# PRM_MPU register map
Vendor: Texas Instruments
Peripheral module from a debugger description file (folder am437x).
Registers are 32-bit, access per field, no defined reset value unless marked. A register's access mark holds for its fields unless they carry their own. Offsets are as the file gives them; lines under a group give offsets from that group; [hi:lo] are bit positions; {n}, {i} and the like mark numbered series; 'fields as' and 'values as' point back to an identical list; <NAME> marks a mode.

## PRM_MPU
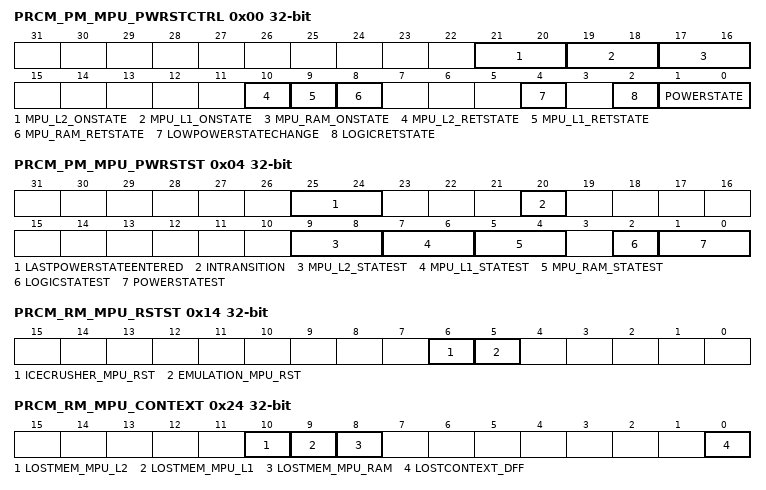
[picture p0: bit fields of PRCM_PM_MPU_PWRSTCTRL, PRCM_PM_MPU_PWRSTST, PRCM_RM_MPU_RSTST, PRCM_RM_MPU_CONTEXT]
0x00 PRCM_PM_MPU_PWRSTCTRL — This register controls the MPU power state to reach upon mpu domain sleep transition
  [21:20] MPU_L2_ONSTATE ro — Default power domain memory state when domain is ON.
    3=en_1_0x3 (Memory bank is on when the domain is ON.)
  [19:18] MPU_L1_ONSTATE ro — Default power domain memory state when domain is ON.
    3=en_1_0x3 (Memory bank is on when the domain is ON.)
  [17:16] MPU_RAM_ONSTATE ro — Default power domain memory state when domain is ON.
    3=en_1_0x3 (Memory bank is on when the domain is ON.)
  [10] MPU_L2_RETSTATE rw — L2 bank state when domain is retention.
    1=en_2_0x1 (Memory is retained when domain is in RETENTION state.); 0=en_1_0x0 (Memory is off when the domain is in the RETENTION state.)
  [9] MPU_L1_RETSTATE rw — L1 bank state when domain is retention.
    values as MPU_L2_RETSTATE
  [8] MPU_RAM_RETSTATE rw — MPU RAM bank state when domain is retention.
    values as MPU_L2_RETSTATE
  [4] LOWPOWERSTATECHANGE rw — Power state change request when domain has already performed a sleep transition. [[br]]Allows going into deeper low power state without waking up the power domain.
    1=en_2_0x1 (Request a low power state change. This bit is automatically cleared when the power state is effectively changed or when power state is ON.); 0=en_1_0x0 (Do not request a low power state change.)
  [2] LOGICRETSTATE rw — Logic state when power domain is RETENTION
    1=en_2_0x1 (Whole logic is retained when domain is in RETENTION state.); 0=en_1_0x0 (Only retention registers are retained and remaing logic is off when the domain is in RETENTION state.)
  [1:0] POWERSTATE rw — Power state control
    3=en_4_0x3 (ON State); 2=en_3_0x2 (RESERVED); 1=en_2_0x1 (RETENTION state); 0=en_1_0x0 (OFF State)
0x04 PRCM_PM_MPU_PWRSTST — This register provides a status on the current MPU power domain state0. [warm reset insensitive]
  [25:24] LASTPOWERSTATEENTERED rw — Last low power state entered. [[br]]Set to 0x3 upon write of the same only. [[br]]This register is intended for debug purpose only.
    3=en_4_0x3 (Power domain was previously ON-ACTIVE); 2=en_3_0x2 (Power domain was previously ON-INACTIVE); 1=en_2_0x1 (Power domain was previously in RETENTION); 0=en_1_0x0 (Power domain was previously OFF)
  [20] INTRANSITION ro — Domain transition status
    1=en_2_0x1 (Power domain transition is in progress.); 0=en_1_0x0 (No on-going transition on power domain)
  [9:8] MPU_L2_STATEST ro — MPU L2 memory state status
    3=en_4_0x3 (Memory is ON); 2=en_3_0x2 (Reserved); 1=en_2_0x1 (Memory is in RETENTION.); 0=en_1_0x0 (Memory is OFF)
  [7:6] MPU_L1_STATEST ro — MPU L1 memory state status
    values as MPU_L2_STATEST
  [5:4] MPU_RAM_STATEST ro — MPU_RAM memory state status
    values as MPU_L2_STATEST
  [2] LOGICSTATEST ro — Logic state status
    1=en_2_0x1 (Logic in domain is ON); 0=en_1_0x0 (Logic in domain is OFF)
  [1:0] POWERSTATEST ro — Current Power State Status
    3=en_3_0x3 (ON State [warm reset insensitive]); 1=en_2_0x1 (RETENTION state); 0=en_1_0x0 (OFF State [warm reset insensitive])
0x14 PRCM_RM_MPU_RSTST — This register logs the different reset sources of the ALWON domain. Each bit is set upon release of the domain reset signal. Must be cleared by software. [warm reset insensitive]
  [6] ICECRUSHER_MPU_RST rw — MPU Processor has been reset due to MPU ICECRUSHER1 reset event
    1=en_2_0x1 (MPU Processor has been reset upon icecursher reset); 0=en_1_0x0 (No icecrusher reset)
  [5] EMULATION_MPU_RST rw — MPU Processor has been reset due to emulation reset source e.g. [[br]]assert reset command initiated by the icepick module
    1=en_2_0x1 (MPU Processor has been reset upon emulation reset); 0=en_1_0x0 (No emulation reset)
0x24 PRCM_RM_MPU_CONTEXT — This register contains dedicated MPU context statuses. [warm reset insensitive]
  [all] fields
    1=en_2_0x1 (Context has been lost); 0=en_1_0x0 (Context has been maintained)
  [10] LOSTMEM_MPU_L2 rw — Specify if memory-based context in MPU_L2 memory bank has been lost due to a previous power transition or other reset source.
  [9] LOSTMEM_MPU_L1 rw — Specify if memory-based context in MPU_L1 memory bank has been lost due to a previous power transition or other reset source.
  [8] LOSTMEM_MPU_RAM rw — Specify if memory-based context in MPU_RAM memory bank has been lost due to a previous power transition or other reset source (not affected by a global warm reset).
  [0] LOSTCONTEXT_DFF rw — Specify if DFF-based context has been lost due to a previous power transition or other reset source. [[br]](set upon assertion of MPU_RST signal)
